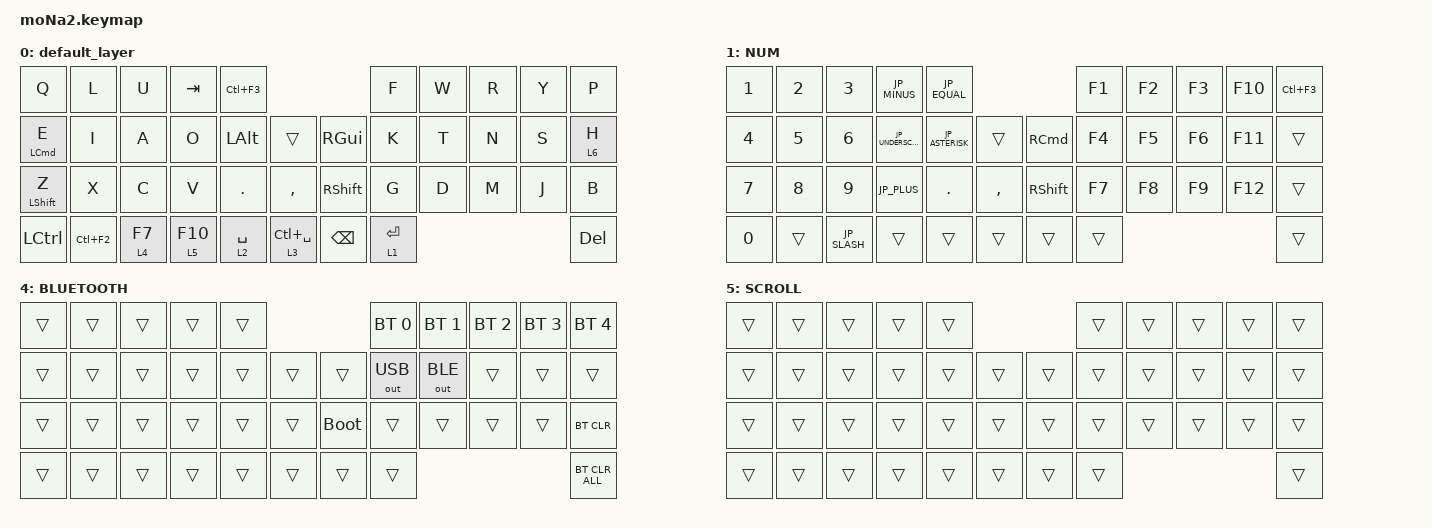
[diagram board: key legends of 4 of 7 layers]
#include <behaviors.dtsi>
#include <dt-bindings/zmk/bt.h>
#include <dt-bindings/zmk/keys.h>
#include <dt-bindings/zmk/pointing.h>
#include <dt-bindings/zmk/outputs.h>
#define ZMK_POINTING_DEFAULT_SCRL_VAL 45

// OS設定を日本語キーボードのまま使用するための変換定義

#define JP_MINUS        MINUS             // -
#define JP_SLASH        SLASH             // /
#define JP_LT           LS(COMMA)         // <
#define JP_GT           LS(DOT)           // >
#define JP_EXCL         LS(N1)            // !
#define JP_HASH         LS(N3)            // #
#define JP_DOLLAR       LS(N4)            // $
#define JP_PERCENT      LS(N5)            // %
#define JP_AMP          LS(N6)            // &
#define JP_SEMICOLON    SEMICOLON         // ;
#define JP_DQUOTE       AT                // "
#define JP_AMPERSAND    CARET             // &
#define JP_QUOTE        AMPERSAND         // '
#define JP_EQUAL        UNDER             // =
#define JP_CARET        EQUAL             // ^
#define JP_YEN          0x89              // ¥
#define JP_PLUS         COLON             // +
#define JP_TILDE        PLUS              // ~
#define JP_PIPE         LS(0x89)          // |
#define JP_AT           LEFT_BRACKET      // @
#define JP_COLON        SINGLE_QUOTE      // :
#define JP_ASTERISK     DOUBLE_QUOTES     // *
#define JP_BACKQUOTE    LEFT_BRACE        // `
#define JP_UNDERSCORE   LS(0x87)          // _
#define JP_LBRACKET     RIGHT_BRACKET     // [
#define JP_RBRACKET     BACKSLASH         // ]
#define JP_LPAREN       ASTERISK          // (
#define JP_RPAREN       LEFT_PARENTHESIS  // )
#define JP_LBRACE       RIGHT_BRACE       // {
#define JP_RBRACE       PIPE              // }
#define JP_KANA         LANGUAGE_1        // かな
#define JP_EISU         LANGUAGE_2        // 英数
#define JP_HANZEN       GRAVE             // 半角/全角
#define JP_QUESTION     LS(SLASH)         // ?

&mt {
    flavor = "balanced";
    quick-tap-ms = <175>;
    require-prior-idle-ms = <150>;
};

/ {
    combos {
        compatible = "zmk,combos";

        combo_shift_enter {
            timeout-ms = <100>;
            key-positions = <22 41>;
            bindings = <&kp LS(ENTER)>;
        };
    };

    macros {
        to_layer_0: to_layer_0 {
            compatible = "zmk,behavior-macro-one-param";
            #binding-cells = <1>;
            bindings = <&to 0 &macro_param_1to1 &kp MACRO_PLACEHOLDER>;
            label = "TO_LAYER_0";
        };
    };

    behaviors {
        lt_to_layer_0: lt_to_layer_0 {
            compatible = "zmk,behavior-hold-tap";
            label = "LAYER_TAP_TO_0";
            bindings = <&mo>, <&to_layer_0>;

            #binding-cells = <2>;
            tapping-term-ms = <200>;
        };

        scroll_up_down: behavior_wheel_up_down {
            compatible = "zmk,behavior-sensor-rotate";
            #sensor-binding-cells = <0>;
            bindings = <&msc SCRL_UP>, <&msc SCRL_DOWN>;

            tap-ms = <50>;
            label = "behavior_sensor_rotate_up_down";
        };

        left_right: left_right {
            compatible = "zmk,behavior-sensor-rotate";
            #sensor-binding-cells = <0>;
            bindings = <&msc SCRL_RIGHT>, <&msc SCRL_LEFT>;

            tap-ms = <50>;
            label = "LEFT_RIGHT";
        };

        mt_z: mt_z {
            compatible = "zmk,behavior-hold-tap";
            #binding-cells = <2>;
            flavor = "tap-preferred";
            tapping-term-ms = <200>;
            quick-tap-ms = <175>;
            require-prior-idle-ms = <150>;
            bindings = <&kp>, <&kp>;

            label = "MT_Z";
        };

        lt_fast: lt_fast {
            compatible = "zmk,behavior-hold-tap";
            #binding-cells = <2>;
            flavor = "balanced";
            tapping-term-ms = <200>;
            quick-tap-ms = <175>;
            bindings = <&mo>, <&kp>;

            label = "LT_FAST";
        };

        lt_scroll: lt_scroll {
            compatible = "zmk,behavior-hold-tap";
            #binding-cells = <2>;
            flavor = "balanced";
            tapping-term-ms = <130>;
            quick-tap-ms = <175>;
            bindings = <&mo>, <&kp>;

            label = "LT_SCROLL";
        };

        undo_redo: undo_redo {
            compatible = "zmk,behavior-sensor-rotate";
            #sensor-binding-cells = <0>;
            bindings = <&kp LC(Z)>, <&kp LC(Y)>;

            tap-ms = <50>;
            label = "UNDO_REDO";
        };

        tab_switch: tab_switch {
            compatible = "zmk,behavior-sensor-rotate";
            #sensor-binding-cells = <0>;
            bindings = <&kp LC(LS(TAB))>, <&kp LC(TAB)>;

            tap-ms = <50>;
            label = "TAB_SWITCH";
        };

        lt_h: lt_h {
            compatible = "zmk,behavior-hold-tap";
            #binding-cells = <2>;
            flavor = "balanced";
            tapping-term-ms = <200>;
            quick-tap-ms = <175>;
            require-prior-idle-ms = <150>;
            bindings = <&mo>, <&kp>;

            label = "LT_H";
        };

        volume_control: volume_control {
            compatible = "zmk,behavior-sensor-rotate";
            #sensor-binding-cells = <0>;
            bindings = <&kp C_VOL_DN>, <&kp C_VOL_UP>;

            tap-ms = <50>;
            label = "VOLUME_CONTROL";
        };

        brightness_control: brightness_control {
            compatible = "zmk,behavior-sensor-rotate";
            #sensor-binding-cells = <0>;
            bindings = <&kp C_BRI_DN>, <&kp C_BRI_UP>;

            tap-ms = <50>;
            label = "BRIGHTNESS_CONTROL";
        };
    };

    keymap {
        compatible = "zmk,keymap";

        default_layer {
            bindings = <
&kp Q               &kp L       &kp U     &kp TAB           &kp LC(F3)                                                 &kp F             &kp W  &kp R  &kp Y  &kp P
&mt LEFT_COMMAND E  &kp I       &kp A     &kp O             &kp LEFT_ALT      &trans                  &kp RIGHT_GUI    &kp K             &kp T  &kp N  &kp S  &lt_h 6 H
&mt_z LEFT_SHIFT Z  &kp X       &kp C     &kp V             &kp PERIOD        &kp COMMA               &kp RIGHT_SHIFT  &kp G             &kp D  &kp M  &kp J  &kp B
&kp LEFT_CONTROL    &kp LC(F2)  &lt 4 F7  &lt_scroll 5 F10  &lt_fast 2 SPACE  &lt_fast 3 LC(SPACE)    &kp BACKSPACE    &lt_fast 1 ENTER                       &kp DEL
            >;

            sensor-bindings = <&scroll_up_down>;
        };

        NUM {
            bindings = <
&kp NUMBER_1  &kp NUMBER_2  &kp NUMBER_3  &kp JP_MINUS       &kp JP_EQUAL                                     &kp F1  &kp F2  &kp F3  &kp F10  &kp LC(F3)
&kp NUMBER_4  &kp N5        &kp NUMBER_6  &kp JP_UNDERSCORE  &kp JP_ASTERISK  &trans       &kp RIGHT_COMMAND  &kp F4  &kp F5  &kp F6  &kp F11  &trans
&kp NUMBER_7  &kp NUMBER_8  &kp NUMBER_9  &kp JP_PLUS        &kp PERIOD       &kp COMMA    &kp RIGHT_SHIFT    &kp F7  &kp F8  &kp F9  &kp F12  &trans
&kp N0        &trans        &kp JP_SLASH  &trans             &trans           &trans       &trans             &trans                           &trans
            >;

            sensor-bindings = <&tab_switch>;
        };

        ARROW {
            bindings = <
&kp ESCAPE        &kp LA(LG(LEFT))      &kp LG(UP_ARROW)    &kp LC(UP_ARROW)       &kp LS(LG(LC(NUMBER_4)))                               &kp ESCAPE  &kp LA(LG(LEFT))        &kp UP_ARROW  &kp LA(LG(RIGHT))  &kp PAGE_UP
&kp LEFT_COMMAND  &kp LG(LEFT_ARROW)    &kp LG(DOWN_ARROW)  &kp LG(RIGHT_ARROW)    &trans                    &trans    &kp RIGHT_COMMAND  &kp HOME    &kp LEFT                &kp DOWN      &kp RIGHT          &kp END
&kp LEFT_SHIFT    &kp LS(LA(LC(LEFT)))  &trans              &kp LS(LC(LA(RIGHT)))  &trans                    &trans    &kp RIGHT_SHIFT    &trans      &kp LC(LA(LEFT_ARROW))  &trans        &kp LA(LC(RIGHT))  &kp PAGE_DOWN
&trans            &trans                &trans              &trans                 &trans                    &trans    &trans             &trans
            >;

            sensor-bindings = <&inc_dec_kp LC(JP_RBRACKET) LG(JP_SEMICOLON)>;
        };

        SYMBOLS {
            bindings = <
&kp JP_PERCENT    &kp JP_DOLLAR  &kp JP_AMP       &kp JP_CARET  &kp JP_SLASH                                    &kp JP_YEN         &kp JP_LBRACE    &kp JP_RBRACE    &kp JP_LT         &kp JP_GT
&kp JP_AT         &kp JP_HASH    &kp JP_ASTERISK  &kp JP_PLUS   &kp JP_EQUAL     &trans        &kp RIGHT_GUI    &kp JP_UNDERSCORE  &kp JP_LPAREN    &kp JP_RPAREN    &kp JP_SEMICOLON  &kp JP_COLON
&kp JP_BACKQUOTE  &kp JP_TILDE   &kp JP_MINUS     &kp JP_EXCL   &kp JP_QUESTION  &kp INSERT    &kp RIGHT_SHIFT  &kp JP_PIPE        &kp JP_LBRACKET  &kp JP_RBRACKET  &kp JP_QUOTE      &kp JP_DQUOTE
&trans            &trans         &trans           &trans        &trans           &trans
            >;

            sensor-bindings = <&inc_dec_kp LC(LG(MINUS)) LC(LG(EQUAL))>;
        };

        BLUETOOTH {
            bindings = <
&trans  &trans  &trans  &trans  &trans                         &bt BT_SEL 0  &bt BT_SEL 1  &bt BT_SEL 2  &bt BT_SEL 3  &bt BT_SEL 4
&trans  &trans  &trans  &trans  &trans  &trans    &trans       &out OUT_USB  &out OUT_BLE  &trans        &trans        &trans
&trans  &trans  &trans  &trans  &trans  &trans    &bootloader  &trans        &trans        &trans        &trans        &bt BT_CLR
&trans  &trans  &trans  &trans  &trans  &trans    &trans       &trans                                                  &bt BT_CLR_ALL
            >;

            sensor-bindings = <&brightness_control>;
        };

        SCROLL {
            bindings = <
&trans  &trans  &trans  &trans  &trans                    &trans  &trans  &trans  &trans  &trans
&trans  &trans  &trans  &trans  &trans  &trans    &trans  &trans  &trans  &trans  &trans  &trans
&trans  &trans  &trans  &trans  &trans  &trans    &trans  &trans  &trans  &trans  &trans  &trans
&trans  &trans  &trans  &trans  &trans  &trans    &trans  &trans                          &trans
            >;

            sensor-bindings = <&volume_control>;
        };

        MOUSE {
            bindings = <
&trans  &trans  &trans  &trans  &trans                    &trans  &mkp MB4              &kp LG(T)  &mkp MB5           &trans
&trans  &trans  &trans  &trans  &trans  &trans    &trans  &trans  &mkp MB1              &mkp MB3   &mkp MB2           &trans
&trans  &trans  &trans  &trans  &trans  &trans    &trans  &trans  &kp LA(LC(LG(LEFT)))  &kp LG(W)  &kp LA(LC(RIGHT))  &trans
&trans  &trans  &trans  &trans  &trans  &trans    &trans  &trans                                                      &trans
            >;

            sensor-bindings = <&scroll_up_down>;
        };
    };
};
